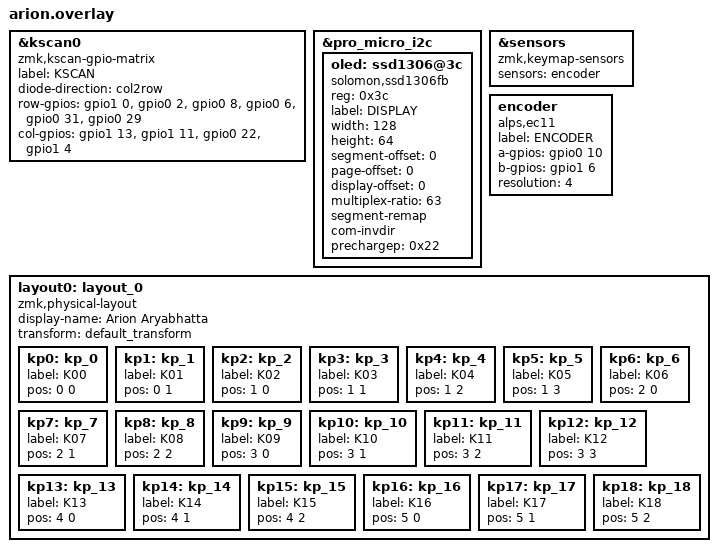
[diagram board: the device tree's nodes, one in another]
#include <dt-bindings/zmk/matrix_transform.h>

&kscan0 {
    compatible = "zmk,kscan-gpio-matrix";
    label = "KSCAN";
    diode-direction = "col2row";

    row-gpios = <&gpio1 0 (GPIO_ACTIVE_HIGH | GPIO_PULL_DOWN)>,
                <&gpio0 2 (GPIO_ACTIVE_HIGH | GPIO_PULL_DOWN)>,
                <&gpio0 8 (GPIO_ACTIVE_HIGH | GPIO_PULL_DOWN)>,
                <&gpio0 6 (GPIO_ACTIVE_HIGH | GPIO_PULL_DOWN)>,
                <&gpio0 31 (GPIO_ACTIVE_HIGH | GPIO_PULL_DOWN)>,
                <&gpio0 29 (GPIO_ACTIVE_HIGH | GPIO_PULL_DOWN)>;

    col-gpios = <&gpio1 13 GPIO_ACTIVE_HIGH>,
                <&gpio1 11 GPIO_ACTIVE_HIGH>,
                <&gpio0 22 GPIO_ACTIVE_HIGH>,
                <&gpio1 4 GPIO_ACTIVE_HIGH>;
};

&pro_micro_i2c {
    status = "okay";

    oled: ssd1306@3c {
        compatible = "solomon,ssd1306fb";
        reg = <0x3c>;
        label = "DISPLAY";
        width = <128>;
        height = <64>;
        segment-offset = <0>;
        page-offset = <0>;
        display-offset = <0>;
        multiplex-ratio = <63>;
        segment-remap;
        com-invdir;
        prechargep = <0x22>;
    };
};

&sensors {
    compatible = "zmk,keymap-sensors";
    sensors = <&encoder>;
};

encoder: encoder {
    compatible = "alps,ec11";
    label = "ENCODER";
    a-gpios = <&gpio0 10 (GPIO_ACTIVE_HIGH | GPIO_PULL_UP)>;
    b-gpios = <&gpio1 6 (GPIO_ACTIVE_HIGH | GPIO_PULL_UP)>;
    resolution = <4>;
    status = "okay";
};

layout0: layout_0 {
    compatible = "zmk,physical-layout";
    display-name = "Arion Aryabhatta";
    transform = <&default_transform>;

    // 🧩 KEY POSITIONS — required for Studio
    kp0: kp_0 { label = "K00"; pos = <0 0>; };
    kp1: kp_1 { label = "K01"; pos = <0 1>; };
    kp2: kp_2 { label = "K02"; pos = <1 0>; };
    kp3: kp_3 { label = "K03"; pos = <1 1>; };
    kp4: kp_4 { label = "K04"; pos = <1 2>; };
    kp5: kp_5 { label = "K05"; pos = <1 3>; };
    kp6: kp_6 { label = "K06"; pos = <2 0>; };
    kp7: kp_7 { label = "K07"; pos = <2 1>; };
    kp8: kp_8 { label = "K08"; pos = <2 2>; };
    kp9: kp_9 { label = "K09"; pos = <3 0>; };
    kp10: kp_10 { label = "K10"; pos = <3 1>; };
    kp11: kp_11 { label = "K11"; pos = <3 2>; };
    kp12: kp_12 { label = "K12"; pos = <3 3>; };
    kp13: kp_13 { label = "K13"; pos = <4 0>; };
    kp14: kp_14 { label = "K14"; pos = <4 1>; };
    kp15: kp_15 { label = "K15"; pos = <4 2>; };
    kp16: kp_16 { label = "K16"; pos = <5 0>; };
    kp17: kp_17 { label = "K17"; pos = <5 1>; };
    kp18: kp_18 { label = "K18"; pos = <5 2>; };
};
